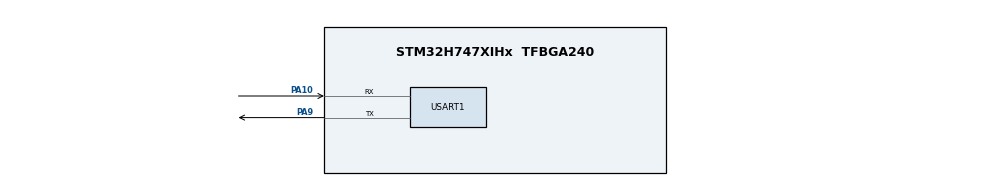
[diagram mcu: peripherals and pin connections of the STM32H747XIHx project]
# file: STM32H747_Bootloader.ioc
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CORTEX_M7.default_mode_Activation=1
CortexM4.IPs=CORTEX_M4\:I,FATFS_M4\:I,FREERTOS_M4\:I,IWDG2\:I,OPENAMP_M4\:I,PDM2PCM_M4\:I,PWR,RCC,RESMGR_UTILITY,SYS_M4\:I,USB_DEVICE_M4\:I,USB_HOST_M4\:I,VREFBUF,WWDG2\:I,GPIO,DMA,BDMA,MDMA,NVIC2\:I
CortexM7.IPs=CORTEX_M7\:I,FATFS_M7\:I,FREERTOS_M7\:I,IWDG1\:I,OPENAMP_M7\:I,PDM2PCM_M7\:I,PWR\:I,RCC\:I,RESMGR_UTILITY\:I,SYS\:I,USB_DEVICE_M7\:I,USB_HOST_M7\:I,VREFBUF\:I,WWDG1\:I,GPIO\:I,DMA\:I,BDMA\:I,MDMA\:I,NVIC1\:I,USART1\:I
Mcu.Family=STM32H7
Mcu.Name=STM32H747XIHx
Mcu.Package=TFBGA240
NVIC1.PriorityGroup=NVIC_PRIORITYGROUP_4
NVIC2.PriorityGroup=NVIC_PRIORITYGROUP_4
PA10.Mode=Asynchronous
PA10.PinAttribute=CortexM7
PA10.Signal=USART1_RX
PA9.Mode=Asynchronous
PA9.PinAttribute=CortexM7
PA9.Signal=USART1_TX
ProjectManager.HeapSize=M4-0x200,M7-0x200
ProjectManager.StackSize=M4-0x400,M7-0x400
ProjectManager.TargetToolchain=STM32CubeIDE
RCC.ADCFreq_Value=129000000
RCC.APB1Freq_Value=64000000
RCC.APB2Freq_Value=32000000
RCC.APB3Freq_Value=64000000
RCC.APB4Freq_Value=64000000
RCC.CortexFreq_Value=64000000
RCC.D2PPRE2=RCC_APB2_DIV2
RCC.HCLKFreq_Value=64000000
RCC.SYSCLKFreq_VALUE=64000000
RCC.USBFreq_Value=129000000
SYS.userName=SYS_M7
USART1.VirtualMode-Asynchronous=VM_ASYNC
VP_SYS_M4_VS_Systick.Mode=SysTick
board=custom

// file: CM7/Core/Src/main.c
/* USER CODE BEGIN Header */
/**
 ******************************************************************************
 * @file           : main.c
 * @brief          : Main program body
 ******************************************************************************
 * @attention
 *
 * Copyright (c) 2026 STMicroelectronics.
 * All rights reserved.
 *
 * This software is licensed under terms that can be found in the LICENSE file
 * in the root directory of this software component.
 * If no LICENSE file comes with this software, it is provided AS-IS.
 *
 ******************************************************************************
 */
/* USER CODE END Header */
#include "main.h"

/* USER CODE BEGIN PD */

/* Start address of the CM7 application image (vector table) */
#define CM7_APP_ADDRESS        0x08020000U

/* Max size of the CM7 application image used for basic range checking */
#define CM7_APP_MAX_SIZE       0x000C0000U  /* example 768KB */

/* DUAL_CORE_BOOT_SYNC_SEQUENCE: Define for dual core boot synchronization    */
/*                             demonstration code based on hardware semaphore */
/* This define is present in both CM7/CM4 projects                            */
/* To comment when developping/debugging on a single core                     */
#define DUAL_CORE_BOOT_SYNC_SEQUENCE

#if defined(DUAL_CORE_BOOT_SYNC_SEQUENCE)
#ifndef HSEM_ID_0
#define HSEM_ID_0 (0U) /* HW semaphore 0*/
#endif
#endif /* DUAL_CORE_BOOT_SYNC_SEQUENCE */

/* USER CODE END PD */

UART_HandleTypeDef huart1;

void SystemClock_Config(void);
static void MPU_Config(void);
static void MX_GPIO_Init(void);
static void MX_USART1_UART_Init(void);
/* USER CODE BEGIN PFP */
typedef void (*pFunction)(void);
/* USER CODE END PFP */

/* USER CODE BEGIN 0 */

/**
 * @brief  Starts the CM4 core.
 * @note   Assumes CM4 boot address is already configured in Option Bytes
 *         (e.g. to 0x08100000). This function only releases CM4 from hold.
 */
static void StartCM4(void) {
	/* Ensure D2 domain (where CM4 lives) is ready before booting CM4 */
	while (__HAL_RCC_GET_FLAG(RCC_FLAG_D2CKRDY) == RESET) {
		/* spin */
	}

	/* Set BOOT_C2 bit: release CM4 so it starts from its boot address (OB) */
	SET_BIT(RCC->GCR, RCC_GCR_BOOT_C2);

	/* Ensure all writes complete and pipeline is flushed before CM4 runs */
	__DSB();
	__ISB();
}

/**
 * @brief  Validates and jumps to the CM7 application.
 * @note   Expects a valid vector table at CM7_APP_ADDRESS (SP + Reset_Handler).
 *         De-initializes the bootloader context (SysTick, HAL, RCC, NVIC,
 *         MPU, caches), then sets VTOR/MSP and branches to the app.
 */
static void JumpToCM7App(void) {
	/* Read initial stack pointer from app vector table */
	uint32_t app_sp = *(__IO uint32_t*) CM7_APP_ADDRESS;

	/* Read reset handler address from app vector table */
	uint32_t app_reset_addr = *(__IO uint32_t*) (CM7_APP_ADDRESS + 4U);
	pFunction app_reset_handler = (pFunction) app_reset_addr;

	/* Check that SP is in a valid CM7 RAM region:
	 - DTCM 0x2000_0000–0x2002_0000 or
	 - D1 SRAM 0x2400_0000–0x2408_0000
	 */
	uint8_t valid_sp = ((app_sp >= 0x20000000U && app_sp <= 0x20020000U) || /* DTCM */
	(app_sp >= 0x24000000U && app_sp <= 0x24080000U)); /* D1 SRAM */

	/* Check reset handler is inside CM7 app flash range */
	uint32_t app_flash_end = CM7_APP_ADDRESS + CM7_APP_MAX_SIZE;
	uint8_t valid_reset = (app_reset_addr >= CM7_APP_ADDRESS
			&& app_reset_addr < app_flash_end);

	if (!(valid_sp && valid_reset)) {
		/* No valid app image detected: stay in bootloader */
		return;
	}

	/* Stop SysTick to avoid further tick interrupts during/after the jump */
	SysTick->CTRL = 0;
	SysTick->LOAD = 0;
	SysTick->VAL = 0;

	/* Disable MPU regions configured by the bootloader */
	HAL_MPU_Disable();
	MPU->CTRL = 0;

	/* Disable instruction cache (and optionally data cache) */
	SCB_DisableICache();
	// SCB_DisableDCache();

	/* Reset clock configuration and HAL state to get closer to reset state */
	HAL_RCC_DeInit();
	HAL_DeInit();

	/* Disable and clear all NVIC interrupts configured by the bootloader */
	for (int i = 0; i < 8; i++) {
		NVIC->ICER[i] = 0xFFFFFFFF;
		NVIC->ICPR[i] = 0xFFFFFFFF;
	}

	/* Point vector table to the CM7 application */
	SCB->VTOR = CM7_APP_ADDRESS;

	/* Load MSP with application's initial stack pointer */
	__set_MSP(app_sp);

	/* Ensure all outstanding memory operations complete before branching */
	__DSB();
	__ISB();

	/* Branch to application's Reset_Handler (never returns if app is OK) */
	app_reset_handler();
}

/* USER CODE END 0 */

int main(void) {

	/* USER CODE BEGIN 1 */
	int32_t timeout;
	/* USER CODE END 1 */
	/* USER CODE BEGIN Boot_Mode_Sequence_0 */

	/* USER CODE END Boot_Mode_Sequence_0 */

	/* MPU Configuration--------------------------------------------------------*/
	MPU_Config();

	/* USER CODE BEGIN Boot_Mode_Sequence_1 */

	/* Wait until CPU2 boots and enters in stop mode or timeout*/
	timeout = 0xFFFF;
	while ((__HAL_RCC_GET_FLAG(RCC_FLAG_D2CKRDY) != RESET) && (timeout-- > 0))
		;
	if (timeout < 0) {
		Error_Handler();
	}

	/* USER CODE END Boot_Mode_Sequence_1 */
	/* MCU Configuration--------------------------------------------------------*/

	/* Reset of all peripherals, Initializes the Flash interface and the Systick. */
	HAL_Init();

	/* Configure the system clock */
	SystemClock_Config();

	/* USER CODE BEGIN Boot_Mode_Sequence_2 */

	/*HW semaphore Clock enable*/
	__HAL_RCC_HSEM_CLK_ENABLE();

	/*Take HSEM */
	HAL_HSEM_FastTake(HSEM_ID_0);
	/*Release HSEM in order to notify the CPU2(CM4)*/
	HAL_HSEM_Release(HSEM_ID_0, 0);

	/* wait until CPU2 wakes up from stop mode */
	timeout = 0xFFFF;
	while ((__HAL_RCC_GET_FLAG(RCC_FLAG_D2CKRDY) == RESET) && (timeout-- > 0))
		;
	if (timeout < 0) {
		Error_Handler();
	}

	/* USER CODE END Boot_Mode_Sequence_2 */

	/* Initialize all configured peripherals */
	MX_GPIO_Init();
	MX_USART1_UART_Init();
	/* USER CODE BEGIN 2 */

	/* Simple bootloader banner on UART1 to confirm CM7 BL is running */
	const char bl_msg[] = "[CM7-BL] Bootloader running...\r\n";
	HAL_UART_Transmit(&huart1, (uint8_t*) bl_msg, sizeof(bl_msg) - 1,
	HAL_MAX_DELAY);

	/* 1. TODO: check a button / command / flag to decide:
	 - stay in bootloader (firmware update mode)
	 - or continue and start applications */

	HAL_Delay(2000);

	/* 2. Start CM4 application (using CM4 boot address from Option Bytes) */
	//StartCM4();

	/* 3. Validate and jump to CM7 application at CM7_APP_ADDRESS */
	JumpToCM7App();

	/* USER CODE END 2 */

	/* Infinite loop */
	/* USER CODE BEGIN WHILE */
	/* If no valid app, stay here (bootloader mode) */
	while (1) {
		/* USER CODE END WHILE */

	}
}

void SystemClock_Config(void) {
	RCC_OscInitTypeDef RCC_OscInitStruct = { 0 };
	RCC_ClkInitTypeDef RCC_ClkInitStruct = { 0 };

	/** Supply configuration update enable
	 */
	HAL_PWREx_ConfigSupply(PWR_DIRECT_SMPS_SUPPLY);

	/** Configure the main internal regulator output voltage
	 */
	__HAL_PWR_VOLTAGESCALING_CONFIG(PWR_REGULATOR_VOLTAGE_SCALE3);

	while (!__HAL_PWR_GET_FLAG(PWR_FLAG_VOSRDY)) {
	}

	/** Initializes the RCC Oscillators according to the specified parameters
	 * in the RCC_OscInitTypeDef structure.
	 */
	RCC_OscInitStruct.OscillatorType = RCC_OSCILLATORTYPE_HSI;
	RCC_OscInitStruct.HSIState = RCC_HSI_DIV1;
	RCC_OscInitStruct.HSICalibrationValue = RCC_HSICALIBRATION_DEFAULT;
	RCC_OscInitStruct.PLL.PLLState = RCC_PLL_NONE;
	if (HAL_RCC_OscConfig(&RCC_OscInitStruct) != HAL_OK) {
		Error_Handler();
	}

	/** Initializes the CPU, AHB and APB buses clocks
	 */
	RCC_ClkInitStruct.ClockType = RCC_CLOCKTYPE_HCLK | RCC_CLOCKTYPE_SYSCLK
			| RCC_CLOCKTYPE_PCLK1 | RCC_CLOCKTYPE_PCLK2 | RCC_CLOCKTYPE_D3PCLK1
			| RCC_CLOCKTYPE_D1PCLK1;
	RCC_ClkInitStruct.SYSCLKSource = RCC_SYSCLKSOURCE_HSI;
	RCC_ClkInitStruct.SYSCLKDivider = RCC_SYSCLK_DIV1;
	RCC_ClkInitStruct.AHBCLKDivider = RCC_HCLK_DIV1;
	RCC_ClkInitStruct.APB3CLKDivider = RCC_APB3_DIV1;
	RCC_ClkInitStruct.APB1CLKDivider = RCC_APB1_DIV1;
	RCC_ClkInitStruct.APB2CLKDivider = RCC_APB2_DIV2;
	RCC_ClkInitStruct.APB4CLKDivider = RCC_APB4_DIV1;

	if (HAL_RCC_ClockConfig(&RCC_ClkInitStruct, FLASH_LATENCY_1) != HAL_OK) {
		Error_Handler();
	}
}

static void MX_USART1_UART_Init(void) {

	huart1.Instance = USART1;
	huart1.Init.BaudRate = 115200;
	huart1.Init.WordLength = UART_WORDLENGTH_8B;
	huart1.Init.StopBits = UART_STOPBITS_1;
	huart1.Init.Parity = UART_PARITY_NONE;
	huart1.Init.Mode = UART_MODE_TX_RX;
	huart1.Init.HwFlowCtl = UART_HWCONTROL_NONE;
	huart1.Init.OverSampling = UART_OVERSAMPLING_16;
	huart1.Init.OneBitSampling = UART_ONE_BIT_SAMPLE_DISABLE;
	huart1.Init.ClockPrescaler = UART_PRESCALER_DIV1;
	huart1.AdvancedInit.AdvFeatureInit = UART_ADVFEATURE_NO_INIT;
	if (HAL_UART_Init(&huart1) != HAL_OK) {
		Error_Handler();
	}
	if (HAL_UARTEx_SetTxFifoThreshold(&huart1, UART_TXFIFO_THRESHOLD_1_8)
			!= HAL_OK) {
		Error_Handler();
	}
	if (HAL_UARTEx_SetRxFifoThreshold(&huart1, UART_RXFIFO_THRESHOLD_1_8)
			!= HAL_OK) {
		Error_Handler();
	}
	if (HAL_UARTEx_DisableFifoMode(&huart1) != HAL_OK) {
		Error_Handler();
	}

}

static void MX_GPIO_Init(void) {

	/* GPIO Ports Clock Enable */
	__HAL_RCC_GPIOA_CLK_ENABLE();

}

/* MPU Configuration */

void MPU_Config(void) {
	MPU_Region_InitTypeDef MPU_InitStruct = { 0 };

	/* Disables the MPU */
	HAL_MPU_Disable();

	/** Initializes and configures the Region and the memory to be protected
	 */
	MPU_InitStruct.Enable = MPU_REGION_ENABLE;
	MPU_InitStruct.Number = MPU_REGION_NUMBER0;
	MPU_InitStruct.BaseAddress = 0x0;
	MPU_InitStruct.Size = MPU_REGION_SIZE_4GB;
	MPU_InitStruct.SubRegionDisable = 0x87;
	MPU_InitStruct.TypeExtField = MPU_TEX_LEVEL0;
	MPU_InitStruct.AccessPermission = MPU_REGION_NO_ACCESS;
	MPU_InitStruct.DisableExec = MPU_INSTRUCTION_ACCESS_DISABLE;
	MPU_InitStruct.IsShareable = MPU_ACCESS_SHAREABLE;
	MPU_InitStruct.IsCacheable = MPU_ACCESS_NOT_CACHEABLE;
	MPU_InitStruct.IsBufferable = MPU_ACCESS_NOT_BUFFERABLE;

	HAL_MPU_ConfigRegion(&MPU_InitStruct);
	/* Enables the MPU */
	HAL_MPU_Enable(MPU_PRIVILEGED_DEFAULT);

}

void Error_Handler(void) {
	__disable_irq();
	while (1) {
	}
}
